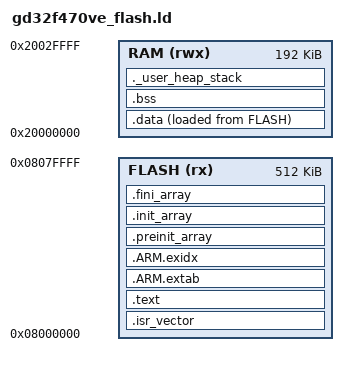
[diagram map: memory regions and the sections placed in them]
ENTRY(Reset_Handler)

MEMORY
{
    FLASH (rx) : ORIGIN = 0x08000000, LENGTH = 512K
    RAM (rwx)  : ORIGIN = 0x20000000, LENGTH = 192K
}

_estack = ORIGIN(RAM) + LENGTH(RAM);

PHDRS
{
    text PT_LOAD FLAGS(5);
    data PT_LOAD FLAGS(6);
    bss PT_NULL FLAGS(6);
}

SECTIONS
{
    .isr_vector : { KEEP(*(.isr_vector)) } > FLASH :text
    .text :
    {
        *(.text*)
        *(.rodata*)
        KEEP(*(.init))
        KEEP(*(.fini))
        . = ALIGN(4);
        _etext = .;
    } > FLASH :text
    .ARM.extab : { *(.ARM.extab* .gnu.linkonce.armextab.*) } > FLASH :text
    .ARM.exidx : { __exidx_start = .; *(.ARM.exidx* .gnu.linkonce.armexidx.*) __exidx_end = .; } > FLASH :text
    .preinit_array : { PROVIDE_HIDDEN(__preinit_array_start = .); KEEP(*(.preinit_array*)) PROVIDE_HIDDEN(__preinit_array_end = .); } > FLASH :text
    .init_array : { PROVIDE_HIDDEN(__init_array_start = .); KEEP(*(SORT(.init_array.*))) KEEP(*(.init_array*)) PROVIDE_HIDDEN(__init_array_end = .); } > FLASH :text
    .fini_array : { PROVIDE_HIDDEN(__fini_array_start = .); KEEP(*(SORT(.fini_array.*))) KEEP(*(.fini_array*)) PROVIDE_HIDDEN(__fini_array_end = .); } > FLASH :text
    . = ALIGN(4);
    _sidata = LOADADDR(.data);
    .data :
    {
        . = ALIGN(4);
        _sdata = .;
        *(.data*)
        . = ALIGN(4);
        _edata = .;
    } > RAM AT > FLASH :data
    .bss (NOLOAD) :
    {
        . = ALIGN(4);
        _sbss = .;
        *(.bss*)
        *(COMMON)
        . = ALIGN(4);
        _ebss = .;
    } > RAM :bss
    ._user_heap_stack (NOLOAD) :
    {
        . = ALIGN(8);
        PROVIDE(end = .);
        PROVIDE(_end = .);
        . = . + 0x800;
        . = . + 0x800;
        . = ALIGN(8);
    } > RAM :bss
}
